# R7FA4W1AD register map
Vendor: Renesas; Series: RA4; File version: 1.0
CPU: CM4 r0p1, little endian, MPU, FPU, VTOR, 4 interrupt priority bits
Registers are 8-bit, read-write, reset 0x0 unless marked. A register's access mark holds for its fields unless they carry their own. Offsets are from the block's base; [hi:lo] are bit positions.

## WDT — Watchdog Timer
Base 0x40044200
0x00 WDTRR reset 0xFF — WDT Refresh Register
  [7:0] WDTRR — WDTRR is an 8-bit register that refreshes the down,counter of the WDT.
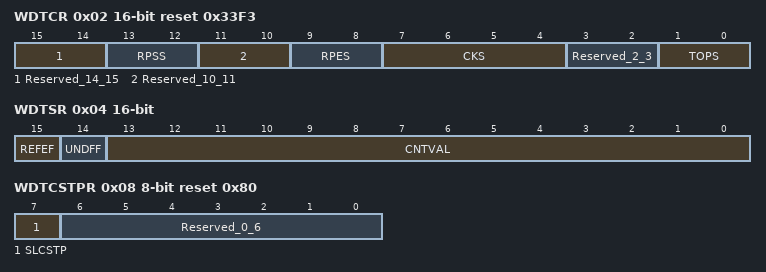
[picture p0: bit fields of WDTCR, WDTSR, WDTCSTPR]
0x02 WDTCR 16-bit reset 0x33F3 — WDT Control Register
  [15:14] Reserved_14_15 — These bits are read as 00. The write value should be 00.
  [13:12] RPSS — Window Start Position Selection
  [11:10] Reserved_10_11 — These bits are read as 00. The write value should be 00.
  [9:8] RPES — Window End Position Selection
  [7:4] CKS — Clock Division Ratio Selection
  [3:2] Reserved_2_3 — These bits are read as 00. The write value should be 00.
  [1:0] TOPS — Timeout Period Selection
0x04 WDTSR 16-bit — WDT Status Register
  [15] REFEF write-0-clears read-modifies — Refresh Error Flag
  [14] UNDFF write-0-clears read-modifies — Underflow Flag
  [13:0] CNTVAL ro — Down,Counter ValueValue counted by the down,counter
0x06 WDTRCR reset 0x80 — WDT Reset Control Register
  [7] RSTIRQS — Reset Interrupt Request Selection
0x08 WDTCSTPR reset 0x80 — WDT Count Stop Control Register
  [7] SLCSTP — Sleep,Mode Count Stop Control
  [6:0] Reserved_0_6 — These bits are read as 0000000. The write value should be 0000000.

## IWDT — Independent Watchdog Timer
Base 0x40044400
0x00 IWDTRR reset 0xFF — IWDT Refresh Register
  [7:0] IWDTRR — The counter is refreshed by writing 0x00 and then writing 0xFF to this register.
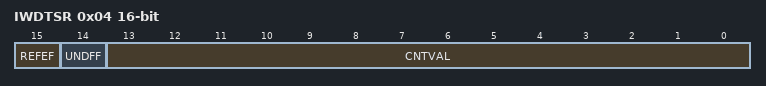
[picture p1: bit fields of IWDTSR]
0x04 IWDTSR 16-bit — IWDT Status Register
  [15] REFEF write-0-clears read-modifies — Refresh Error Flag
  [14] UNDFF write-0-clears read-modifies — Underflow Flag
  [13:0] CNTVAL ro — Counter ValueValue counted by the counter

## PORT0 — Port 0 Control Registers
Base 0x40040000
Same registers: PORT5 0x400400A0, PORT6 0x400400C0, PORT7 0x400400E0, PORT8 0x40040100, PORT9 0x40040120
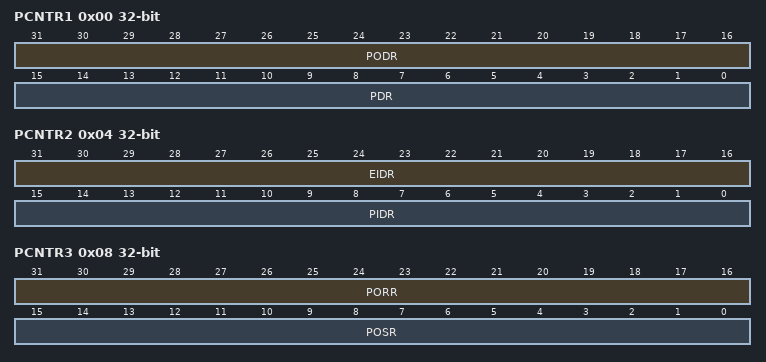
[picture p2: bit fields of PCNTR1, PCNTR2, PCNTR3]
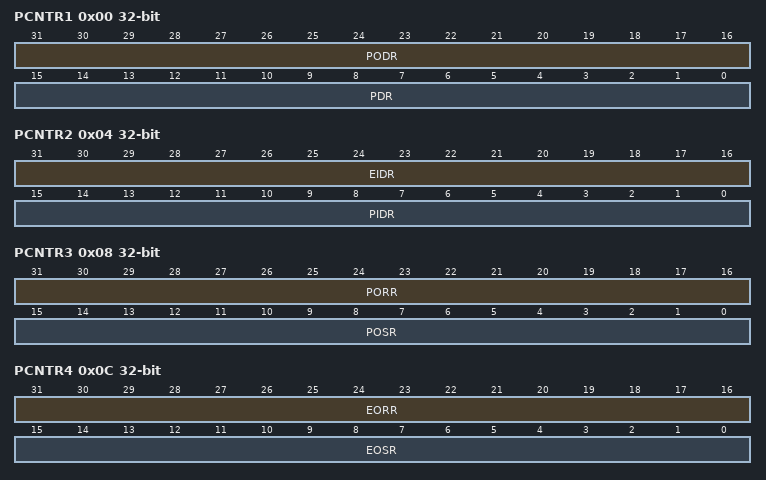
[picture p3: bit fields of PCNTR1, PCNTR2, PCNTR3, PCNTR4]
0x00 PCNTR1 32-bit — Port Control Register 1
  [31:16] PODR — Pmn Output Data
  [15:0] PDR — Pmn Direction
0x00 PODR 16-bit (alternate view of PCNTR1) — Output data register
  [15:0] PODR — Pmn Output Data
0x02 PDR 16-bit (alternate view of PCNTR1) — Data direction register
  [15:0] PDR — Pmn Direction
0x04 PCNTR2 32-bit ro (reset mask 0xFFFF0000) — Port Control Register 2
  [31:16] EIDR — Pmn Event Input Data
  [15:0] PIDR — Pmn Input Data
0x06 PIDR 16-bit ro reset not defined (alternate view of PCNTR2) — Input data register
  [15:0] PIDR — Pmn Input Data
0x08 PCNTR3 32-bit wo — Port Control Register 3
  [31:16] PORR — Pmn Output Reset
  [15:0] POSR — Pmn Output Set
0x08 PORR 16-bit wo (alternate view of PCNTR3) — Output reset register
  [15:0] PORR — Pmn Output Reset
0x0A POSR 16-bit wo (alternate view of PCNTR3) — Output set register
  [15:0] POSR — Pmn Output Set

## PORT1 — Port 1 Control Registers
Base 0x40040020
Same registers: PORT2 0x40040040, PORT3 0x40040060, PORT4 0x40040080
0x00 PCNTR1 32-bit — Port Control Register 1
  [31:16] PODR — Pmn Output Data
  [15:0] PDR — Pmn Direction
0x00 PODR 16-bit (alternate view of PCNTR1) — Output data register
  [15:0] PODR — Pmn Output Data
0x02 PDR 16-bit (alternate view of PCNTR1) — Data direction register
  [15:0] PDR — Pmn Direction
0x04 PCNTR2 32-bit ro (reset mask 0xFFFF0000) — Port Control Register 2
  [31:16] EIDR — Pmn Event Input Data
  [15:0] PIDR — Pmn Input Data
0x04 EIDR 16-bit ro reset not defined (alternate view of PCNTR2) — Event input data register
  [15:0] EIDR — Pmn Event Input Data
0x06 PIDR 16-bit ro reset not defined (alternate view of PCNTR2) — Input data register
  [15:0] PIDR — Pmn Input Data
0x08 PCNTR3 32-bit wo — Port Control Register 3
  [31:16] PORR — Pmn Output Reset
  [15:0] POSR — Pmn Output Set
0x08 PORR 16-bit wo (alternate view of PCNTR3) — Output set register
  [15:0] PORR — Pmn Output Reset
0x0A POSR 16-bit wo (alternate view of PCNTR3) — Output reset register
  [15:0] POSR — Pmn Output Set
0x0C PCNTR4 32-bit — Port Control Register 4
  [31:16] EORR — Pmn Event Output Reset
  [15:0] EOSR — Pmn Event Output Set
0x0C EORR 16-bit (alternate view of PCNTR4) — Event output set register
  [15:0] EORR — Pmn Event Output Reset
0x0E EOSR 16-bit (alternate view of PCNTR4) — Event output reset register
  [15:0] EOSR — Pmn Event Output Set
